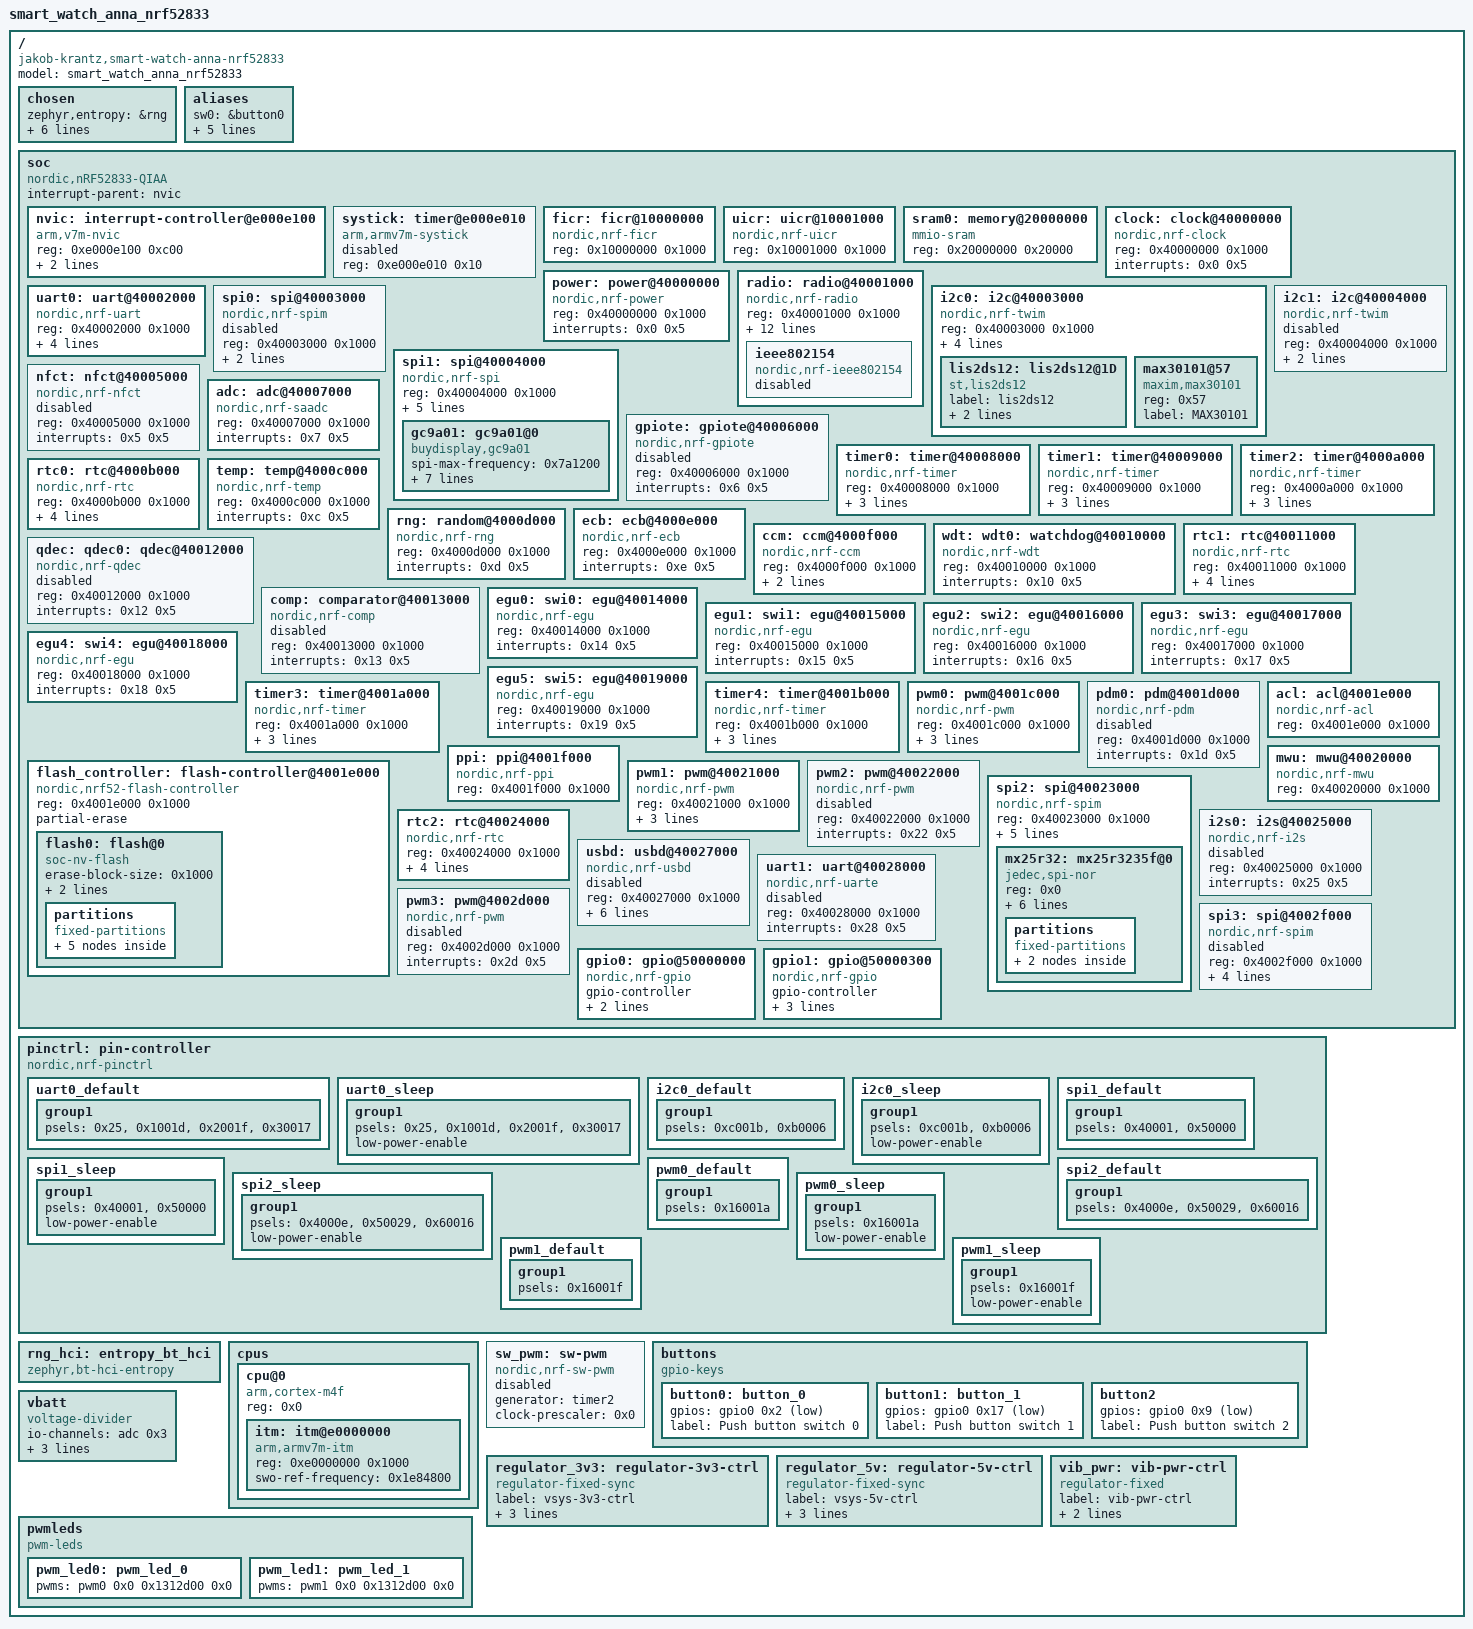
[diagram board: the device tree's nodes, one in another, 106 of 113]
/dts-v1/;

/ {
	#address-cells = < 0x1 >;
	#size-cells = < 0x1 >;
	model = "smart_watch_anna_nrf52833";
	compatible = "jakob-krantz,smart-watch-anna-nrf52833";
	chosen {
		zephyr,entropy = &rng;
		zephyr,flash-controller = &flash_controller;
		zephyr,console = &uart0;
		zephyr,sram = &sram0;
		zephyr,flash = &flash0;
		zephyr,display = &gc9a01;
		zephyr,code-partition = &slot0_partition;
	};
	aliases {
		sw0 = &button0;
		sw1 = &button1;
		sw2 = &button2;
		accelerometer = &lis2ds12;
		pwm-led0 = &pwm_led0;
		pwm-led1 = &pwm_led1;
	};
	soc {
		#address-cells = < 0x1 >;
		#size-cells = < 0x1 >;
		compatible = "nordic,nRF52833-QIAA", "nordic,nRF52833", "nordic,nRF52", "simple-bus";
		interrupt-parent = < &nvic >;
		ranges;
		nvic: interrupt-controller@e000e100 {
			#address-cells = < 0x1 >;
			compatible = "arm,v7m-nvic";
			reg = < 0xe000e100 0xc00 >;
			interrupt-controller;
			#interrupt-cells = < 0x2 >;
			arm,num-irq-priority-bits = < 0x3 >;
			phandle = < 0x1 >;
		};
		systick: timer@e000e010 {
			compatible = "arm,armv7m-systick";
			reg = < 0xe000e010 0x10 >;
			status = "disabled";
		};
		ficr: ficr@10000000 {
			compatible = "nordic,nrf-ficr";
			reg = < 0x10000000 0x1000 >;
			status = "okay";
		};
		uicr: uicr@10001000 {
			compatible = "nordic,nrf-uicr";
			reg = < 0x10001000 0x1000 >;
			status = "okay";
		};
		sram0: memory@20000000 {
			compatible = "mmio-sram";
			reg = < 0x20000000 0x20000 >;
		};
		clock: clock@40000000 {
			compatible = "nordic,nrf-clock";
			reg = < 0x40000000 0x1000 >;
			interrupts = < 0x0 0x5 >;
			status = "okay";
		};
		power: power@40000000 {
			compatible = "nordic,nrf-power";
			reg = < 0x40000000 0x1000 >;
			interrupts = < 0x0 0x5 >;
			status = "okay";
		};
		radio: radio@40001000 {
			compatible = "nordic,nrf-radio";
			reg = < 0x40001000 0x1000 >;
			interrupts = < 0x1 0x5 >;
			status = "okay";
			dfe-supported;
			ieee802154-supported;
			ble-2mbps-supported;
			ble-coded-phy-supported;
			tx-high-power-supported;
			dfe-antenna-num = < 0xa >;
			dfe-pdu-antenna = < 0x1 >;
			dfegpio0-gpios = < &gpio1 0x1 0x0 >;
			dfegpio1-gpios = < &gpio1 0x1 0x0 >;
			dfegpio2-gpios = < &gpio1 0x1 0x0 >;
			dfegpio3-gpios = < &gpio1 0x1 0x0 >;
			ieee802154: ieee802154 {
				compatible = "nordic,nrf-ieee802154";
				status = "disabled";
			};
		};
		uart0: uart@40002000 {
			compatible = "nordic,nrf-uart";
			reg = < 0x40002000 0x1000 >;
			interrupts = < 0x2 0x5 >;
			status = "okay";
			current-speed = < 0x1c200 >;
			pinctrl-0 = < &uart0_default >;
			pinctrl-1 = < &uart0_sleep >;
			pinctrl-names = "default", "sleep";
		};
		i2c0: i2c@40003000 {
			compatible = "nordic,nrf-twim";
			#address-cells = < 0x1 >;
			#size-cells = < 0x0 >;
			reg = < 0x40003000 0x1000 >;
			clock-frequency = < 0x61a80 >;
			interrupts = < 0x3 0x5 >;
			status = "okay";
			pinctrl-0 = < &i2c0_default >;
			pinctrl-1 = < &i2c0_sleep >;
			pinctrl-names = "default", "sleep";
			lis2ds12: lis2ds12@1D {
				compatible = "st,lis2ds12", "st,lis2ds";
				label = "lis2ds12";
				reg = < 0x1d >;
				irq-gpios = < &gpio0 0x1d 0x0 &gpio0 0x1c 0x0 >;
			};
			max30101@57 {
				status = "okay";
				compatible = "maxim,max30101";
				reg = < 0x57 >;
				label = "MAX30101";
			};
		};
		spi0: spi@40003000 {
			compatible = "nordic,nrf-spim";
			#address-cells = < 0x1 >;
			#size-cells = < 0x0 >;
			reg = < 0x40003000 0x1000 >;
			interrupts = < 0x3 0x5 >;
			max-frequency = < 0x7a1200 >;
			status = "disabled";
		};
		i2c1: i2c@40004000 {
			compatible = "nordic,nrf-twim";
			#address-cells = < 0x1 >;
			#size-cells = < 0x0 >;
			reg = < 0x40004000 0x1000 >;
			clock-frequency = < 0x186a0 >;
			interrupts = < 0x4 0x5 >;
			status = "disabled";
		};
		spi1: spi@40004000 {
			compatible = "nordic,nrf-spi";
			#address-cells = < 0x1 >;
			#size-cells = < 0x0 >;
			reg = < 0x40004000 0x1000 >;
			interrupts = < 0x4 0x5 >;
			max-frequency = < 0x7a1200 >;
			status = "okay";
			pinctrl-0 = < &spi1_default >;
			pinctrl-1 = < &spi1_sleep >;
			pinctrl-names = "default", "sleep";
			cs-gpios = < &gpio0 0x10 0x1 >;
			gc9a01: gc9a01@0 {
				compatible = "buydisplay,gc9a01";
				status = "okay";
				spi-max-frequency = < 0x7a1200 >;
				reg = < 0x0 >;
				width = < 0xf0 >;
				label = "buydisplay_gc9a01";
				height = < 0xf0 >;
				bl-gpios = < &gpio0 0x1a 0x0 >;
				reset-gpios = < &gpio0 0x3 0x0 >;
				dc-gpios = < &gpio1 0x0 0x0 >;
			};
		};
		nfct: nfct@40005000 {
			compatible = "nordic,nrf-nfct";
			reg = < 0x40005000 0x1000 >;
			interrupts = < 0x5 0x5 >;
			status = "disabled";
		};
		gpiote: gpiote@40006000 {
			compatible = "nordic,nrf-gpiote";
			reg = < 0x40006000 0x1000 >;
			interrupts = < 0x6 0x5 >;
			status = "disabled";
		};
		adc: adc@40007000 {
			compatible = "nordic,nrf-saadc";
			reg = < 0x40007000 0x1000 >;
			interrupts = < 0x7 0x5 >;
			status = "okay";
			#io-channel-cells = < 0x1 >;
			phandle = < 0x11 >;
		};
		timer0: timer@40008000 {
			compatible = "nordic,nrf-timer";
			status = "okay";
			reg = < 0x40008000 0x1000 >;
			cc-num = < 0x4 >;
			interrupts = < 0x8 0x5 >;
			prescaler = < 0x0 >;
		};
		timer1: timer@40009000 {
			compatible = "nordic,nrf-timer";
			status = "okay";
			reg = < 0x40009000 0x1000 >;
			cc-num = < 0x4 >;
			interrupts = < 0x9 0x5 >;
			prescaler = < 0x0 >;
		};
		timer2: timer@4000a000 {
			compatible = "nordic,nrf-timer";
			status = "okay";
			reg = < 0x4000a000 0x1000 >;
			cc-num = < 0x4 >;
			interrupts = < 0xa 0x5 >;
			prescaler = < 0x0 >;
			phandle = < 0x10 >;
		};
		rtc0: rtc@4000b000 {
			compatible = "nordic,nrf-rtc";
			reg = < 0x4000b000 0x1000 >;
			cc-num = < 0x3 >;
			interrupts = < 0xb 0x5 >;
			status = "okay";
			clock-frequency = < 0x8000 >;
			prescaler = < 0x1 >;
		};
		temp: temp@4000c000 {
			compatible = "nordic,nrf-temp";
			reg = < 0x4000c000 0x1000 >;
			interrupts = < 0xc 0x5 >;
			status = "okay";
		};
		rng: random@4000d000 {
			compatible = "nordic,nrf-rng";
			reg = < 0x4000d000 0x1000 >;
			interrupts = < 0xd 0x5 >;
			status = "okay";
		};
		ecb: ecb@4000e000 {
			compatible = "nordic,nrf-ecb";
			reg = < 0x4000e000 0x1000 >;
			interrupts = < 0xe 0x5 >;
			status = "okay";
		};
		ccm: ccm@4000f000 {
			compatible = "nordic,nrf-ccm";
			reg = < 0x4000f000 0x1000 >;
			interrupts = < 0xf 0x5 >;
			length-field-length-8-bits;
			status = "okay";
		};
		wdt: wdt0: watchdog@40010000 {
			compatible = "nordic,nrf-wdt";
			reg = < 0x40010000 0x1000 >;
			interrupts = < 0x10 0x5 >;
			status = "okay";
		};
		rtc1: rtc@40011000 {
			compatible = "nordic,nrf-rtc";
			reg = < 0x40011000 0x1000 >;
			cc-num = < 0x4 >;
			interrupts = < 0x11 0x5 >;
			status = "okay";
			clock-frequency = < 0x8000 >;
			prescaler = < 0x1 >;
		};
		qdec: qdec0: qdec@40012000 {
			compatible = "nordic,nrf-qdec";
			reg = < 0x40012000 0x1000 >;
			interrupts = < 0x12 0x5 >;
			status = "disabled";
		};
		comp: comparator@40013000 {
			compatible = "nordic,nrf-comp";
			reg = < 0x40013000 0x1000 >;
			interrupts = < 0x13 0x5 >;
			status = "disabled";
			#io-channel-cells = < 0x1 >;
		};
		egu0: swi0: egu@40014000 {
			compatible = "nordic,nrf-egu", "nordic,nrf-swi";
			reg = < 0x40014000 0x1000 >;
			interrupts = < 0x14 0x5 >;
			status = "okay";
		};
		egu1: swi1: egu@40015000 {
			compatible = "nordic,nrf-egu", "nordic,nrf-swi";
			reg = < 0x40015000 0x1000 >;
			interrupts = < 0x15 0x5 >;
			status = "okay";
		};
		egu2: swi2: egu@40016000 {
			compatible = "nordic,nrf-egu", "nordic,nrf-swi";
			reg = < 0x40016000 0x1000 >;
			interrupts = < 0x16 0x5 >;
			status = "okay";
		};
		egu3: swi3: egu@40017000 {
			compatible = "nordic,nrf-egu", "nordic,nrf-swi";
			reg = < 0x40017000 0x1000 >;
			interrupts = < 0x17 0x5 >;
			status = "okay";
		};
		egu4: swi4: egu@40018000 {
			compatible = "nordic,nrf-egu", "nordic,nrf-swi";
			reg = < 0x40018000 0x1000 >;
			interrupts = < 0x18 0x5 >;
			status = "okay";
		};
		egu5: swi5: egu@40019000 {
			compatible = "nordic,nrf-egu", "nordic,nrf-swi";
			reg = < 0x40019000 0x1000 >;
			interrupts = < 0x19 0x5 >;
			status = "okay";
		};
		timer3: timer@4001a000 {
			compatible = "nordic,nrf-timer";
			status = "okay";
			reg = < 0x4001a000 0x1000 >;
			cc-num = < 0x6 >;
			interrupts = < 0x1a 0x5 >;
			prescaler = < 0x0 >;
		};
		timer4: timer@4001b000 {
			compatible = "nordic,nrf-timer";
			status = "okay";
			reg = < 0x4001b000 0x1000 >;
			cc-num = < 0x6 >;
			interrupts = < 0x1b 0x5 >;
			prescaler = < 0x0 >;
		};
		pwm0: pwm@4001c000 {
			compatible = "nordic,nrf-pwm";
			reg = < 0x4001c000 0x1000 >;
			interrupts = < 0x1c 0x5 >;
			status = "okay";
			#pwm-cells = < 0x3 >;
			pinctrl-0 = < &pwm0_default >;
			pinctrl-1 = < &pwm0_sleep >;
			pinctrl-names = "default", "sleep";
			phandle = < 0x12 >;
		};
		pdm0: pdm@4001d000 {
			compatible = "nordic,nrf-pdm";
			reg = < 0x4001d000 0x1000 >;
			interrupts = < 0x1d 0x5 >;
			status = "disabled";
		};
		acl: acl@4001e000 {
			compatible = "nordic,nrf-acl";
			reg = < 0x4001e000 0x1000 >;
			status = "okay";
		};
		flash_controller: flash-controller@4001e000 {
			compatible = "nordic,nrf52-flash-controller";
			reg = < 0x4001e000 0x1000 >;
			partial-erase;
			#address-cells = < 0x1 >;
			#size-cells = < 0x1 >;
			flash0: flash@0 {
				compatible = "soc-nv-flash";
				erase-block-size = < 0x1000 >;
				write-block-size = < 0x4 >;
				reg = < 0x0 0x80000 >;
				partitions {
					compatible = "fixed-partitions";
					#address-cells = < 0x1 >;
					#size-cells = < 0x1 >;
					boot_partition: partition@0 {
						label = "mcuboot";
						reg = < 0x0 0xc000 >;
					};
					slot0_partition: partition@c000 {
						label = "image-0";
						reg = < 0xc000 0x32000 >;
					};
					slot1_partition: partition@3e000 {
						label = "image-1";
						reg = < 0x3e000 0x32000 >;
					};
					scratch_partition: partition@70000 {
						label = "image-scratch";
						reg = < 0x70000 0xe000 >;
					};
					storage_partition: partition@7e000 {
						label = "storage";
						reg = < 0x7e000 0x2000 >;
					};
				};
			};
		};
		ppi: ppi@4001f000 {
			compatible = "nordic,nrf-ppi";
			reg = < 0x4001f000 0x1000 >;
			status = "okay";
		};
		mwu: mwu@40020000 {
			compatible = "nordic,nrf-mwu";
			reg = < 0x40020000 0x1000 >;
			status = "okay";
		};
		pwm1: pwm@40021000 {
			compatible = "nordic,nrf-pwm";
			reg = < 0x40021000 0x1000 >;
			interrupts = < 0x21 0x5 >;
			status = "okay";
			#pwm-cells = < 0x3 >;
			pinctrl-0 = < &pwm1_default >;
			pinctrl-1 = < &pwm1_sleep >;
			pinctrl-names = "default", "sleep";
			phandle = < 0x13 >;
		};
		pwm2: pwm@40022000 {
			compatible = "nordic,nrf-pwm";
			reg = < 0x40022000 0x1000 >;
			interrupts = < 0x22 0x5 >;
			status = "disabled";
			#pwm-cells = < 0x3 >;
		};
		spi2: spi@40023000 {
			compatible = "nordic,nrf-spim";
			#address-cells = < 0x1 >;
			#size-cells = < 0x0 >;
			reg = < 0x40023000 0x1000 >;
			interrupts = < 0x23 0x5 >;
			max-frequency = < 0x7a1200 >;
			status = "okay";
			pinctrl-0 = < &spi2_default >;
			pinctrl-1 = < &spi2_sleep >;
			pinctrl-names = "default", "sleep";
			cs-gpios = < &gpio0 0xf 0x1 >;
			mx25r32: mx25r3235f@0 {
				compatible = "jedec,spi-nor";
				reg = < 0x0 >;
				spi-max-frequency = < 0x7a1200 >;
				label = "MX25R32";
				size = < 0x2000000 >;
				jedec-id = [ C2 28 16 ];
				reset-gpios = < &gpio0 0x14 0x11 >;
				wp-gpios = < &gpio0 0x7 0x1 >;
				partitions {
					compatible = "fixed-partitions";
					#address-cells = < 0x1 >;
					#size-cells = < 0x1 >;
					partition_cfg: partition@0 {
						label = "littlefs_cfg";
						reg = < 0x0 0x10000 >;
					};
					partition_lfs: partition@10000 {
						label = "littlefs";
						reg = < 0x10000 0x80000 >;
					};
				};
			};
		};
		rtc2: rtc@40024000 {
			compatible = "nordic,nrf-rtc";
			reg = < 0x40024000 0x1000 >;
			cc-num = < 0x4 >;
			interrupts = < 0x24 0x5 >;
			status = "okay";
			clock-frequency = < 0x8000 >;
			prescaler = < 0x1 >;
		};
		i2s0: i2s@40025000 {
			compatible = "nordic,nrf-i2s";
			#address-cells = < 0x1 >;
			#size-cells = < 0x0 >;
			reg = < 0x40025000 0x1000 >;
			interrupts = < 0x25 0x5 >;
			status = "disabled";
		};
		usbd: usbd@40027000 {
			compatible = "nordic,nrf-usbd";
			reg = < 0x40027000 0x1000 >;
			interrupts = < 0x27 0x5 >;
			num-bidir-endpoints = < 0x1 >;
			num-in-endpoints = < 0x7 >;
			num-out-endpoints = < 0x7 >;
			num-isoin-endpoints = < 0x1 >;
			num-isoout-endpoints = < 0x1 >;
			status = "disabled";
		};
		uart1: uart@40028000 {
			compatible = "nordic,nrf-uarte";
			reg = < 0x40028000 0x1000 >;
			interrupts = < 0x28 0x5 >;
			status = "disabled";
		};
		pwm3: pwm@4002d000 {
			compatible = "nordic,nrf-pwm";
			reg = < 0x4002d000 0x1000 >;
			interrupts = < 0x2d 0x5 >;
			status = "disabled";
			#pwm-cells = < 0x3 >;
		};
		spi3: spi@4002f000 {
			compatible = "nordic,nrf-spim";
			#address-cells = < 0x1 >;
			#size-cells = < 0x0 >;
			reg = < 0x4002f000 0x1000 >;
			interrupts = < 0x2f 0x5 >;
			max-frequency = < 0x1e84800 >;
			rx-delay-supported;
			rx-delay = < 0x2 >;
			status = "disabled";
		};
		gpio0: gpio@50000000 {
			compatible = "nordic,nrf-gpio";
			gpio-controller;
			reg = < 0x50000000 0x200 0x50000500 0x300 >;
			#gpio-cells = < 0x2 >;
			status = "okay";
			port = < 0x0 >;
			phandle = < 0x7 >;
		};
		gpio1: gpio@50000300 {
			compatible = "nordic,nrf-gpio";
			gpio-controller;
			reg = < 0x50000300 0x200 0x50000800 0x300 >;
			#gpio-cells = < 0x2 >;
			ngpios = < 0xa >;
			status = "okay";
			port = < 0x1 >;
			phandle = < 0x2 >;
		};
	};
	pinctrl: pin-controller {
		compatible = "nordic,nrf-pinctrl";
		uart0_default: uart0_default {
			phandle = < 0x3 >;
			group1 {
				psels = < 0x25 >, < 0x1001d >, < 0x2001f >, < 0x30017 >;
			};
		};
		uart0_sleep: uart0_sleep {
			phandle = < 0x4 >;
			group1 {
				psels = < 0x25 >, < 0x1001d >, < 0x2001f >, < 0x30017 >;
				low-power-enable;
			};
		};
		i2c0_default: i2c0_default {
			phandle = < 0x5 >;
			group1 {
				psels = < 0xc001b >, < 0xb0006 >;
			};
		};
		i2c0_sleep: i2c0_sleep {
			phandle = < 0x6 >;
			group1 {
				psels = < 0xc001b >, < 0xb0006 >;
				low-power-enable;
			};
		};
		spi1_default: spi1_default {
			phandle = < 0x8 >;
			group1 {
				psels = < 0x40001 >, < 0x50000 >;
			};
		};
		spi1_sleep: spi1_sleep {
			phandle = < 0x9 >;
			group1 {
				psels = < 0x40001 >, < 0x50000 >;
				low-power-enable;
			};
		};
		spi2_default: spi2_default {
			phandle = < 0xe >;
			group1 {
				psels = < 0x4000e >, < 0x50029 >, < 0x60016 >;
			};
		};
		spi2_sleep: spi2_sleep {
			phandle = < 0xf >;
			group1 {
				psels = < 0x4000e >, < 0x50029 >, < 0x60016 >;
				low-power-enable;
			};
		};
		pwm0_default: pwm0_default {
			phandle = < 0xa >;
			group1 {
				psels = < 0x16001a >;
			};
		};
		pwm0_sleep: pwm0_sleep {
			phandle = < 0xb >;
			group1 {
				psels = < 0x16001a >;
				low-power-enable;
			};
		};
		pwm1_default: pwm1_default {
			phandle = < 0xc >;
			group1 {
				psels = < 0x16001f >;
			};
		};
		pwm1_sleep: pwm1_sleep {
			phandle = < 0xd >;
			group1 {
				psels = < 0x16001f >;
				low-power-enable;
			};
		};
	};
	rng_hci: entropy_bt_hci {
		compatible = "zephyr,bt-hci-entropy";
		status = "okay";
	};
	cpus {
		#address-cells = < 0x1 >;
		#size-cells = < 0x0 >;
		cpu@0 {
			device_type = "cpu";
			compatible = "arm,cortex-m4f";
			reg = < 0x0 >;
			#address-cells = < 0x1 >;
			#size-cells = < 0x1 >;
			itm: itm@e0000000 {
				compatible = "arm,armv7m-itm";
				reg = < 0xe0000000 0x1000 >;
				swo-ref-frequency = < 0x1e84800 >;
			};
		};
	};
	sw_pwm: sw-pwm {
		compatible = "nordic,nrf-sw-pwm";
		status = "disabled";
		generator = < &timer2 >;
		clock-prescaler = < 0x0 >;
		#pwm-cells = < 0x3 >;
	};
	buttons {
		compatible = "gpio-keys";
		button0: button_0 {
			gpios = < &gpio0 0x2 0x11 >;
			label = "Push button switch 0";
		};
		button1: button_1 {
			gpios = < &gpio0 0x17 0x11 >;
			label = "Push button switch 1";
		};
		button2: button2 {
			gpios = < &gpio0 0x9 0x11 >;
			label = "Push button switch 2";
		};
	};
	vbatt {
		compatible = "voltage-divider";
		io-channels = < &adc 0x3 >;
		output-ohms = < 0x35b60 >;
		full-ohms = < 0x1a3ec0 >;
		power-gpios = < &gpio0 0x4 0x0 >;
	};
	regulator_3v3: regulator-3v3-ctrl {
		compatible = "regulator-fixed-sync", "regulator-fixed";
		label = "vsys-3v3-ctrl";
		regulator-name = "display";
		enable-gpios = < &gpio0 0x3 0x1 >;
		regulator-boot-on;
	};
	regulator_5v: regulator-5v-ctrl {
		compatible = "regulator-fixed-sync", "regulator-fixed";
		label = "vsys-5v-ctrl";
		regulator-name = "max30101";
		enable-gpios = < &gpio0 0x1f 0x1 >;
		regulator-boot-on;
	};
	vib_pwr: vib-pwr-ctrl {
		compatible = "regulator-fixed";
		label = "vib-pwr-ctrl";
		regulator-name = "vib-pwr-ctrl";
		enable-gpios = < &gpio0 0xc 0x0 >;
	};
	pwmleds {
		compatible = "pwm-leds";
		pwm_led0: pwm_led_0 {
			pwms = < &pwm0 0x0 0x1312d00 0x0 >;
		};
		pwm_led1: pwm_led_1 {
			pwms = < &pwm1 0x0 0x1312d00 0x0 >;
		};
	};
};
